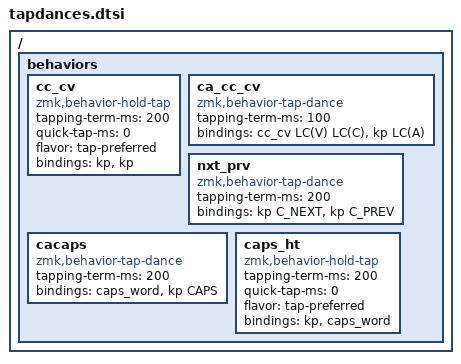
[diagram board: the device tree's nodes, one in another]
/ {
    behaviors {
        cc_cv: cc_cv {
        compatible = "zmk,behavior-hold-tap";
        #binding-cells = <2>;
        tapping-term-ms = <200>;
        quick-tap-ms = <0>;
        flavor = "tap-preferred";
        bindings = <&kp>, <&kp>;
        };
        ca_cc_cv: ca_cc_cv {
            compatible = "zmk,behavior-tap-dance";
            #binding-cells = <0>;
            tapping-term-ms = <100>;
            bindings = <&cc_cv LC(V) LC(C)>, <&kp LC(A)>;
        };
        nxt_prv: nxt_prv {
            compatible = "zmk,behavior-tap-dance";
            #binding-cells = <0>;
            tapping-term-ms = <200>;
            bindings = <&kp C_NEXT>, <&kp C_PREV>;
        };
        cacaps: cacaps {
            compatible = "zmk,behavior-tap-dance";
            #binding-cells = <0>;
            tapping-term-ms = <200>;
            bindings = <&caps_word>, <&kp CAPS>;
        };
        caps_ht: caps_ht {
        compatible = "zmk,behavior-hold-tap";
        #binding-cells = <2>;
        tapping-term-ms = <200>;
        quick-tap-ms = <0>;
        flavor = "tap-preferred";
        bindings = <&kp>, <&caps_word>;
        };
    };
};
